# PRU_ICSSG0_PR1_MII_RT_PR1_MII_RT_CFG_local register map
Vendor: Texas Instruments
Peripheral module from a debugger description file (folder am65x).
Registers are 32-bit, access per field, reset 0x0 unless marked. A register's access mark holds for its fields unless they carry their own. Offsets are as the file gives them; lines under a group give offsets from that group; [hi:lo] are bit positions; {n}, {i} and the like mark numbered series; 'fields as' and 'values as' point back to an identical list; <NAME> marks a mode.

## PRU_ICSSG0_PR1_MII_RT_PR1_MII_RT_CFG
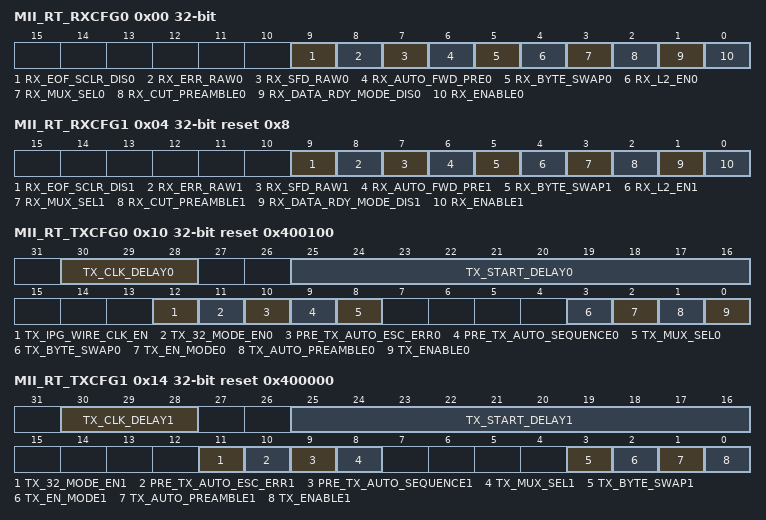
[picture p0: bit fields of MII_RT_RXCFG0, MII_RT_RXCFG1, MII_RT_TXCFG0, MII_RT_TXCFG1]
0x00 MII_RT_RXCFG0 — RX Configuration 0 Register. This register contains the configuration variables for the RX path. is attached to PRU0 core and controls which RX port is attached to PRU0.
  [9] RX_EOF_SCLR_DIS0 rw — 0h = RX_EOF flag in R31 and RXL2 is selfcleared by HW when RX2L is enabled
  [8] RX_ERR_RAW0 rw — 0h = ERR Raw Mode Disabled
  [7] RX_SFD_RAW0 rw — 0h = SFD Raw Mode Disabled
  [6] RX_AUTO_FWD_PRE0 rw — Auto Forward Preamble Mode
  [5] RX_BYTE_SWAP0 rw — Controls the order of the Byte0/1 placement for RX R31 and RX L2.
  [4] RX_L2_EN0 rw — 0h = Disables RX L2 buffer.
  [3] RX_MUX_SEL0 rw — 0h = Select MII RX Data from Port 0
  [2] RX_CUT_PREAMBLE0 rw — 0h = All data from Ethernet PHY are passed on to PRU register.
  [1] RX_DATA_RDY_MODE_DIS0 rw — 0h = R31:16 is DATA_RDY mapeed
  [0] RX_ENABLE0 rw — This enables RX traffic which is currently selected by RX_MUX_SELECT
0x04 MII_RT_RXCFG1 reset 0x8 — RX Configuration 1 Register. This register contains the configuration variables for the RX path. is attached to PRU1 core and controls which RX port is attached to PRU1.
  [9] RX_EOF_SCLR_DIS1 rw — 0h = RX_EOF flag in R31 and RXL2 is selfcleared by HW when RX2L is enabled
  [8] RX_ERR_RAW1 rw — 0h = ERR Raw Mode Disabled
  [7] RX_SFD_RAW1 rw — 0h = SFD Raw Mode Disabled
  [6] RX_AUTO_FWD_PRE1 rw — Auto Forward Preamble Mode
  [5] RX_BYTE_SWAP1 rw — Controls the order of the Byte0/1 placement for RX R31 and RX L2.
  [4] RX_L2_EN1 rw — 0h = Disables RX L2 buffer.
  [3] RX_MUX_SEL1 rw — 0h = Select MII RX Data from Port 0
  [2] RX_CUT_PREAMBLE1 rw — 0h = All data from Ethernet PHY are passed on to PRU register.
  [1] RX_DATA_RDY_MODE_DIS1 rw — 0h = R31:16 is DATA_RDY mapeed
  [0] RX_ENABLE1 rw — This enables RX traffic which is currently selected by RX_MUX_SELECT
0x10 MII_RT_TXCFG0 reset 0x400100 — TX Control Register 0. This register contains the control information for the transmit path on one of the MII interfaces. is attached to Port TX0 and controls which PRU core is selected for TX0.
  [30:28] TX_CLK_DELAY0 rw — Number of MII_RT clock cycles to wait before launching data on the MII interface.
  [25:16] TX_START_DELAY0 rw — The time interval after which transmit interface starts sending data to MII interface after receiving RXDV for the current frame.
  [12] TX_IPG_WIRE_CLK_EN rw — 0h = Use ICSSGn_CORE_CLK (where n = 0 to 1) core clock for the TX_IPG counter 1h = Use the TX interface clock for the TX_IPG counter Note: Using TX interface clock the user should see zero jitter as long as the data is ready to transmit.
  [11] TX_32_MODE_EN0 rw — 0h = Disable 32-bit Data Push mode
  [10] PRE_TX_AUTO_ESC_ERR0 rw — This bit enables the HW actions required to implement the ESC Error handing table.
  [9] PRE_TX_AUTO_SEQUENCE0 rw — When set to one, it enables automated sequencing of transmit state machine based on events on receiver path that is connected to the respective transmitter.
  [8] TX_MUX_SEL0 rw — 0h = TX data from PRU0 is selected
  [3] TX_BYTE_SWAP0 rw — Controls the order of the Byte0/1 placement for TX R30.
  [2] TX_EN_MODE0 rw — 0h = Disables TX_ENABLE self clr for a TX_EOF event iep_cmp[3] for TX0 and iep_cmp[4] for TX1
  [1] TX_AUTO_PREAMBLE0 rw — 0h = PRU will provide full pre-amble
  [0] TX_ENABLE0 rw — 0h = TX PORT is disabled/stopped immediately
0x14 MII_RT_TXCFG1 reset 0x400000 — TX Control Register 1. This register contains the control information for the transmit path on one of the MII interfaces. is attached to Port TX1 and controls which PRU core is selected for TX1.
  [30:28] TX_CLK_DELAY1 rw — Number of MII_RT clock cycles to wait before launching data on the MII interface. Note: In order to guarantee the MII_G_RT I/O timing values published in the device data sheet, the PRU_ICSSG ICSSGn_CORE_CLK (where n = 0 to 2) core clock must be configured for 200 MHz, 225 MHz or 250 MHz and the TX_CLK_DELAY0 bit field in the
  [25:16] TX_START_DELAY1 rw — The time interval after which transmit interface starts sending data to MII interface after receiving RXDV for the current frame.
  [11] TX_32_MODE_EN1 rw — 0h = Disable 32-bit Data Push mode
  [10] PRE_TX_AUTO_ESC_ERR1 rw — This bit enables the HW actions required to implement the ESC Error handing table.
  [9] PRE_TX_AUTO_SEQUENCE1 rw — When set to one, it enables automated sequencing of transmit state machine based on events on receiver path that is connected to the respective transmitter.
  [8] TX_MUX_SEL1 rw — 0h = TX data from PRU0 is selected
  [3] TX_BYTE_SWAP1 rw — Controls the order of the Byte0/1 placement for TX R30.
  [2] TX_EN_MODE1 rw — 0h = Disables TX_ENABLE self clr for a TX_EOF event iep_cmp[3] for TX0 and iep_cmp[4] for TX1
  [1] TX_AUTO_PREAMBLE1 rw — 0h = PRU will provide full pre-amble
  [0] TX_ENABLE1 rw — 0h = TX PORT is disabled/stopped immediately
0x20 MII_RT_TX_CRC0 ro — Transmit CRC32 Register 0. It contains CRC which PRU core can read.
  [31:0] TX_CRC0 — FCS (CRC32) data can be read by PRU core for diagnostics
0x24 MII_RT_TX_CRC1 ro — Transmit CRC32 Register 1. It contains CRC which PRU core can read.
  [31:0] TX_CRC1 — FCS (CRC32) data can be read by PRU for diagnostics
0x30 MII_RT_TX_IPG0 reset 0x28 — TX IPG Register 0.
  [15:0] TX_IPG0 rw — Define the minimum Inter Packet Gap. When When TX_IPG_WIRE_CLK_EN = 1h. This defines the minimum of TX interface clock cycles between the end of a frame and the start of a new frame 0h = 1 TX interface clock Note: In SGMII 100M mode, it will be &lt;n&gt; = &lt;n&gt; +5 TX interface clocks When software does an update, it takes 4 SGMII/RGMII/MII TX_CLKs before it goes into effect Min Values: If the user violate, will get a jitter. The root cause most likely is that the data is not ready. TX MII Odd Nibble is NOT supported in this mode.
0x34 MII_RT_TX_IPG1 rw reset 0x28 — TX IPG Register 1.
  [15:0] TX_IPG1 — Define the minimum Inter Packet Gap. When When TX_IPG_WIRE_CLK_EN = 1h. This defines the minimum of TX interface clock cycles between the end of a frame and the start of a new frame 0h = 1 TX interface clock Note: In SGMII 100M mode, it will be &lt;n&gt; = &lt;n&gt; +5 TX interface clocks When software does an update, it takes 4 SGMII/RGMII/MII TX_CLKs before it goes into effect Min Values: If the user violate, will get a jitter. The root cause most likely is that the data is not ready. TX MII Odd Nibble is NOT supported in this mode.
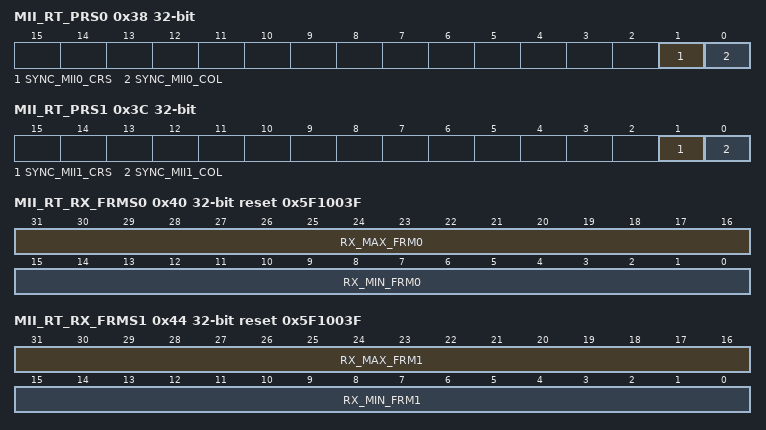
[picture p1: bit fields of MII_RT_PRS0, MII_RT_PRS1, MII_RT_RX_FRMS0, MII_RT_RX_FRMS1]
0x38 MII_RT_PRS0 ro — PORT_RAW_STATUS Register 0.
  [1] SYNC_MII0_CRS — Read the current state of PR1_MII0_CRS
  [0] SYNC_MII0_COL — Read the current state of PR1_MII0_COL
0x3C MII_RT_PRS1 ro — PORT_RAW_STATUS Register 1.
  [1] SYNC_MII1_CRS — Read the current state of PR1_MII1_CRS
  [0] SYNC_MII1_COL — Read the current state of PR1_MII1_COL
0x40 MII_RT_RX_FRMS0 rw reset 0x5F1003F — RX Frame Size Register 0.
  [31:16] RX_MAX_FRM0 — If the FRAME total byte count is more than defined value, RX_MAX_FRM_ERR will get set.
  [15:0] RX_MIN_FRM0 — If the FRAME total byte count is less than defined value, RX_MIN_FRM_ERR will get set.
0x44 MII_RT_RX_FRMS1 rw reset 0x5F1003F — RX Frame Size Register 1.
  [31:16] RX_MAX_FRM1 — If the FRAME total byte count is more than defined value, RX_MAX_FRM_ERR will get set.
  [15:0] RX_MIN_FRM1 — If the FRAME total byte count is less than defined value, RX_MIN_FRM_ERR will get set.
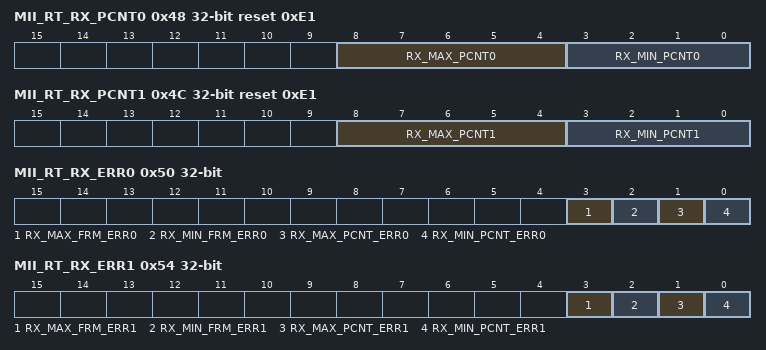
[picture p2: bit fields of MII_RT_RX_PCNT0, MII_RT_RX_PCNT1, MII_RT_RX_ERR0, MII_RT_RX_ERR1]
0x48 MII_RT_RX_PCNT0 reset 0xE1 — RX Preamble Cnt Register 0.
  [8:4] RX_MAX_PCNT0 rw — Define the max number of nibbles until first SFD/SMD is matched.
  [3:0] RX_MIN_PCNT0 rw — Define the minimum number of nibbles before SFD 0xD5
0x4C MII_RT_RX_PCNT1 reset 0xE1 — RX Preamble Cnt Register 1.
  [8:4] RX_MAX_PCNT1 rw — Define the max number of nibbles until first SFD/SMD is matched.
  [3:0] RX_MIN_PCNT1 rw — Define the minimum number of nibbles before SFD 0xD5
0x50 MII_RT_RX_ERR0 — RX Error Register 0.
  [3] RX_MAX_FRM_ERR0 rw — Set when the FRAME total byte count is more than defined value.
  [2] RX_MIN_FRM_ERR0 rw — Set when the FRAME total byte count is less than defined value.
  [1] RX_MAX_PCNT_ERR0 rw — Set when of x nibbles before SFD 0xD5 is more than defined value.
  [0] RX_MIN_PCNT_ERR0 rw — Set when of 0x5 before SFD 0xD5 is less than defined value.
0x54 MII_RT_RX_ERR1 — RX Error Register 1.
  [3] RX_MAX_FRM_ERR1 rw — Set when the FRAME total byte count is more than defined value.
  [2] RX_MIN_FRM_ERR1 rw — Set when the FRAME total byte count is less than defined value.
  [1] RX_MAX_PCNT_ERR1 rw — Set when of x nibbles before SFD 0xD5 is more than defined value.
  [0] RX_MIN_PCNT_ERR1 rw — Set when of 0x5 before SFD 0xD5 is less than defined value.
0x60 MII_RT_RX_FIFO_LEVEL0 ro — RX FIFO Level 0 Register.
  [7:0] RX_FIFO_LEVEL0 — Define the number of valid bytes in the RX FIFO.
0x64 MII_RT_RX_FIFO_LEVEL1 ro — RX FIFO Level 1 Register.
  [7:0] RX_FIFO_LEVEL1 — Define the number of valid bytes in the RX FIFO.
0x68 MII_RT_TX_FIFO_LEVEL0 ro — TX FIFO Register 0.
  [7:0] TX_FIFO_LEVEL0 — Define the number of valid nibbles in the TX FIFO.
0x6C MII_RT_TX_FIFO_LEVEL1 ro — TX FIFO Register 1.
  [7:0] TX_FIFO_LEVEL1 — Define the number of valid nibbles in the TX FIFO.
